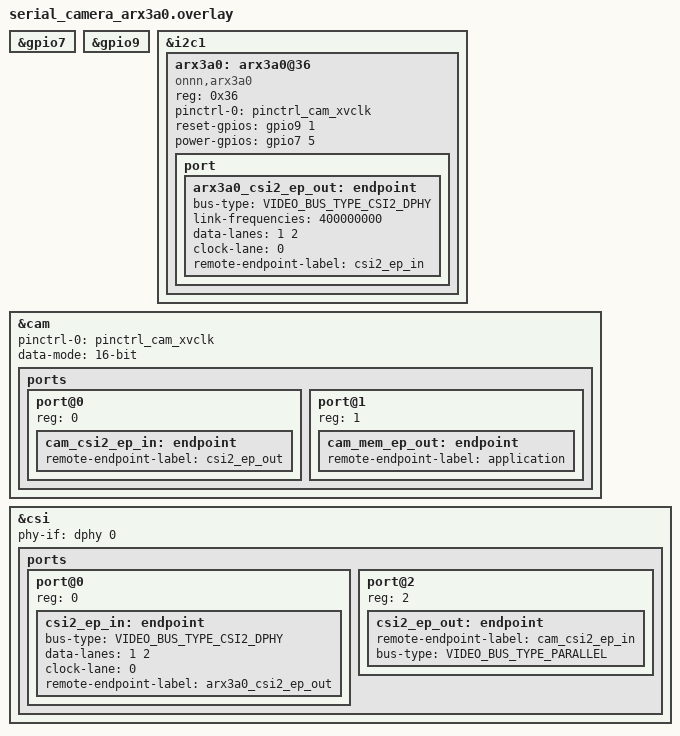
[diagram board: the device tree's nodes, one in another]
/* Copyright (C) 2025 Alif Semiconductor - All Rights Reserved.
 * Use, distribution and modification of this code are permitted under the
 * terms stated in the Alif Semiconductor Software License Agreement.
 *
 * You should have received a copy of the Alif Semiconductor Software
 * License Agreement with this file. If not, please write to:
 * contact@alifsemi.com, or visit: https://alifsemi.com/license
 */

#include <dt-bindings/pinctrl/ensemble-pinctrl.h>
#include <dt-bindings/i2c/i2c.h>
#include <dt-bindings/gpio/gpio.h>
#include <dt-bindings/video/video-interfaces.h>

&gpio7 {
	status = "okay";
};

&gpio9 {
	status = "okay";
};

&i2c1 {
	status = "okay";

	arx3a0: arx3a0@36 {
		compatible = "onnn,arx3a0";
		reg = <0x36>;
		pinctrl-0 = < &pinctrl_cam_xvclk >;
		pinctrl-names = "default";
		reset-gpios = <&gpio9 1 GPIO_ACTIVE_HIGH>;
		power-gpios = <&gpio7 5 GPIO_ACTIVE_HIGH>;

		status = "okay";

		port {
			arx3a0_csi2_ep_out: endpoint {
				bus-type = <VIDEO_BUS_TYPE_CSI2_DPHY>;
				link-frequencies = < 400000000 >;
				data-lanes = <1 2>;
				clock-lane = <0>;

				remote-endpoint-label = "csi2_ep_in";
			};
		};
	};
};

&cam {
	status = "okay";

	pinctrl-0 = <&pinctrl_cam_xvclk>;
	pinctrl-names = "default";

	data-mode = "16-bit";

	ports {
		#address-cells = <1>;
		#size-cells = <0>;

		/* MIPI CSI-2 bus endpoint. */
		port@0 {
			reg = <0>;
			cam_csi2_ep_in: endpoint {
				remote-endpoint-label = "csi2_ep_out";
			};
		};

		/* Video buffer output endpoint. */
		port@1 {
			reg = <1>;
			cam_mem_ep_out: endpoint {
				remote-endpoint-label = "application";
			};
		};
	};
};

&csi {
	status = "okay";

	/* RX-DPHY */
	phy-if = <&dphy 0>;
	ports {
		#address-cells = <1>;
		#size-cells = <0>;
		port@0 {
			reg = <0>;
			csi2_ep_in: endpoint {
				bus-type = <VIDEO_BUS_TYPE_CSI2_DPHY>;
				data-lanes = <1 2>;
				clock-lane = <0>;

				remote-endpoint-label = "arx3a0_csi2_ep_out";
			};
		};
		port@2 {
			reg = <2>;
			csi2_ep_out: endpoint {
				remote-endpoint-label = "cam_csi2_ep_in";
				bus-type = <VIDEO_BUS_TYPE_PARALLEL>;
			};
		};
	};
};
